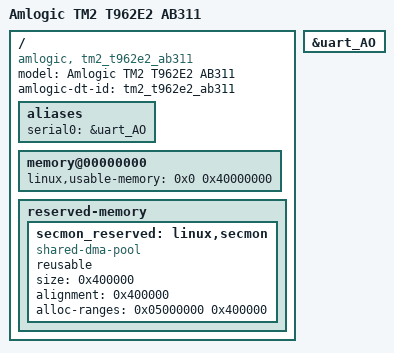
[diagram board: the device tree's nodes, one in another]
/*
 * arch/arm/boot/dts/amlogic/tm2_revb_pxp.dts
 *
 * Copyright (C) 2017 Amlogic, Inc. All rights reserved.
 *
 * This program is free software; you can redistribute it and/or modify
 * it under the terms of the GNU General Public License as published by
 * the Free Software Foundation; either version 2 of the License, or
 * (at your option) any later version.
 *
 * This program is distributed in the hope that it will be useful, but WITHOUT
 * ANY WARRANTY; without even the implied warranty of MERCHANTABILITY or
 * FITNESS FOR A PARTICULAR PURPOSE.  See the GNU General Public License for
 * more details.
 *
 */

/dts-v1/;

#include "mesontm2_revb.dtsi"

/ {
	model = "Amlogic TM2 T962E2 AB311";
	amlogic-dt-id = "tm2_t962e2_ab311";
	compatible = "amlogic, tm2_t962e2_ab311";

	aliases {
		serial0 = &uart_AO;
	};

	memory@00000000 {
		device_type = "memory";
		linux,usable-memory = <0x0 0x40000000>;
	};

	reserved-memory {
		#address-cells = <1>;
		#size-cells = <1>;
		ranges;
		/* global autoconfigured region for contiguous allocations */

		secmon_reserved: linux,secmon {
			compatible = "shared-dma-pool";
			reusable;
			size = <0x400000>;
			alignment = <0x400000>;
			alloc-ranges = <0x05000000 0x400000>;
		};

	}; /* end of reserved-memory */
};

&uart_AO {
	status = "okay";
};
